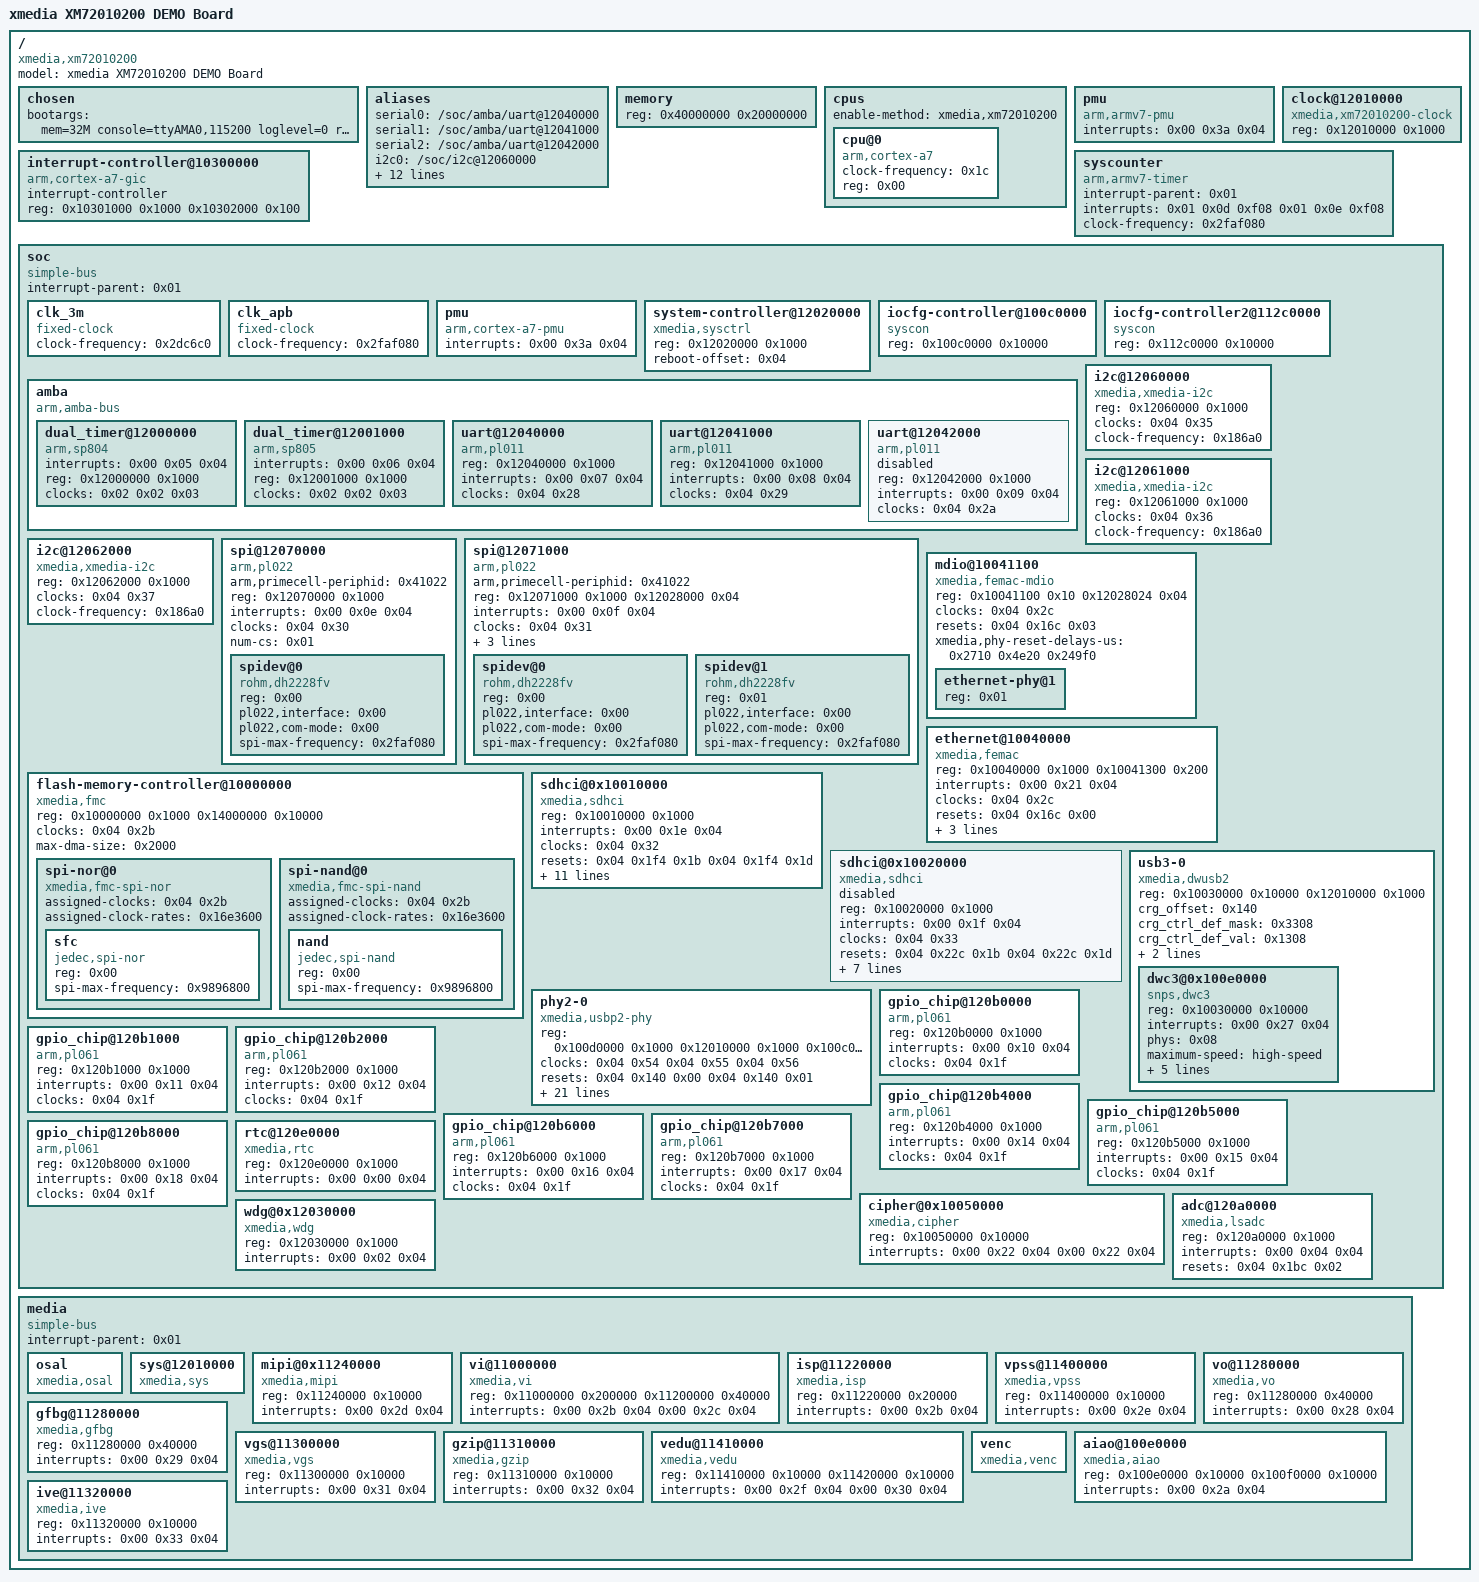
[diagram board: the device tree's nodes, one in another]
/dts-v1/;

/ {
	#address-cells = <0x01>;
	#size-cells = <0x01>;
	model = "xmedia XM72010200 DEMO Board";
	compatible = "xmedia,xm72010200";

	chosen {
		bootargs = "mem=32M console=ttyAMA0,115200 loglevel=0 root=/dev/mtdblock2 rootfstype=jffs2 rw mtdparts=sfc:128K(boot),3M(kernel),3M(rootfs)";
	};

	aliases {
		serial0 = "/soc/amba/uart@12040000";
		serial1 = "/soc/amba/uart@12041000";
		serial2 = "/soc/amba/uart@12042000";
		i2c0 = "/soc/i2c@12060000";
		i2c1 = "/soc/i2c@12061000";
		i2c2 = "/soc/i2c@12062000";
		spi0 = "/soc/spi@12070000";
		spi1 = "/soc/spi@12071000";
		gpio0 = "/soc/gpio_chip@120b0000";
		gpio1 = "/soc/gpio_chip@120b1000";
		gpio2 = "/soc/gpio_chip@120b2000";
		gpio4 = "/soc/gpio_chip@120b4000";
		gpio5 = "/soc/gpio_chip@120b5000";
		gpio6 = "/soc/gpio_chip@120b6000";
		gpio7 = "/soc/gpio_chip@120b7000";
		gpio8 = "/soc/gpio_chip@120b8000";
	};

	memory {
		device_type = "memory";
		reg = <0x40000000 0x20000000>;
	};

	cpus {
		#address-cells = <0x01>;
		#size-cells = <0x00>;
		enable-method = "xmedia,xm72010200";

		cpu@0 {
			device_type = "cpu";
			compatible = "arm,cortex-a7";
			clock-frequency = <0x1c>;
			reg = <0x00>;
		};
	};

	pmu {
		compatible = "arm,armv7-pmu";
		interrupts = <0x00 0x3a 0x04>;
	};

	clock@12010000 {
		compatible = "xmedia,xm72010200-clock\0syscon";
		#address-cells = <0x01>;
		#size-cells = <0x01>;
		#clock-cells = <0x01>;
		#reset-cells = <0x02>;
		reg = <0x12010000 0x1000>;
		linux,phandle = <0x04>;
		phandle = <0x04>;
	};

	interrupt-controller@10300000 {
		compatible = "arm,cortex-a7-gic";
		#interrupt-cells = <0x03>;
		#address-cells = <0x00>;
		interrupt-controller;
		reg = <0x10301000 0x1000 0x10302000 0x100>;
		linux,phandle = <0x01>;
		phandle = <0x01>;
	};

	syscounter {
		compatible = "arm,armv7-timer";
		interrupt-parent = <0x01>;
		interrupts = <0x01 0x0d 0xf08 0x01 0x0e 0xf08>;
		clock-frequency = <0x2faf080>;
	};

	soc {
		#address-cells = <0x01>;
		#size-cells = <0x01>;
		compatible = "simple-bus";
		interrupt-parent = <0x01>;
		ranges;

		clk_3m {
			compatible = "fixed-clock";
			#clock-cells = <0x00>;
			clock-frequency = <0x2dc6c0>;
			linux,phandle = <0x02>;
			phandle = <0x02>;
		};

		clk_apb {
			compatible = "fixed-clock";
			#clock-cells = <0x00>;
			clock-frequency = <0x2faf080>;
			linux,phandle = <0x03>;
			phandle = <0x03>;
		};

		pmu {
			compatible = "arm,cortex-a7-pmu";
			interrupts = <0x00 0x3a 0x04>;
		};

		system-controller@12020000 {
			compatible = "xmedia,sysctrl";
			reg = <0x12020000 0x1000>;
			reboot-offset = <0x04>;
			#clock-cells = <0x01>;
		};

		iocfg-controller@100c0000 {
			compatible = "syscon";
			reg = <0x100c0000 0x10000>;
			linux,phandle = <0x06>;
			phandle = <0x06>;
		};

		iocfg-controller2@112c0000 {
			compatible = "syscon";
			reg = <0x112c0000 0x10000>;
			linux,phandle = <0x07>;
			phandle = <0x07>;
		};

		amba {
			#address-cells = <0x01>;
			#size-cells = <0x01>;
			compatible = "arm,amba-bus";
			ranges;

			dual_timer@12000000 {
				compatible = "arm,sp804\0arm,primecell";
				interrupts = <0x00 0x05 0x04>;
				reg = <0x12000000 0x1000>;
				clocks = <0x02 0x02 0x03>;
				clock-names = "timer00\0timer01\0apb_pclk";
				status = "okay";
			};

			dual_timer@12001000 {
				compatible = "arm,sp805\0arm,primecel5";
				interrupts = <0x00 0x06 0x04>;
				reg = <0x12001000 0x1000>;
				clocks = <0x02 0x02 0x03>;
				clock-names = "timer10\0timer11\0apb_pclk";
				status = "okay";
			};

			uart@12040000 {
				compatible = "arm,pl011\0arm,primecell";
				reg = <0x12040000 0x1000>;
				interrupts = <0x00 0x07 0x04>;
				clocks = <0x04 0x28>;
				clock-names = "apb_pclk";
				status = "okay";
			};

			uart@12041000 {
				compatible = "arm,pl011\0arm,primecell";
				reg = <0x12041000 0x1000>;
				interrupts = <0x00 0x08 0x04>;
				clocks = <0x04 0x29>;
				clock-names = "apb_pclk";
				status = "okay";
			};

			uart@12042000 {
				compatible = "arm,pl011\0arm,primecell";
				reg = <0x12042000 0x1000>;
				interrupts = <0x00 0x09 0x04>;
				clocks = <0x04 0x2a>;
				clock-names = "apb_pclk";
				status = "disabled";
			};
		};

		i2c@12060000 {
			compatible = "xmedia,xmedia-i2c";
			reg = <0x12060000 0x1000>;
			clocks = <0x04 0x35>;
			status = "okay";
			clock-frequency = <0x186a0>;
		};

		i2c@12061000 {
			compatible = "xmedia,xmedia-i2c";
			reg = <0x12061000 0x1000>;
			clocks = <0x04 0x36>;
			status = "okay";
			clock-frequency = <0x186a0>;
		};

		i2c@12062000 {
			compatible = "xmedia,xmedia-i2c";
			reg = <0x12062000 0x1000>;
			clocks = <0x04 0x37>;
			status = "okay";
			clock-frequency = <0x186a0>;
		};

		spi@12070000 {
			compatible = "arm,pl022\0arm,primecell";
			arm,primecell-periphid = <0x41022>;
			reg = <0x12070000 0x1000>;
			interrupts = <0x00 0x0e 0x04>;
			clocks = <0x04 0x30>;
			clock-names = "apb_pclk";
			#address-cells = <0x01>;
			#size-cells = <0x00>;
			status = "okay";
			num-cs = <0x01>;

			spidev@0 {
				compatible = "rohm,dh2228fv";
				reg = <0x00>;
				pl022,interface = <0x00>;
				pl022,com-mode = <0x00>;
				spi-max-frequency = <0x2faf080>;
			};
		};

		spi@12071000 {
			compatible = "arm,pl022\0arm,primecell";
			arm,primecell-periphid = <0x41022>;
			reg = <0x12071000 0x1000 0x12028000 0x04>;
			interrupts = <0x00 0x0f 0x04>;
			clocks = <0x04 0x31>;
			clock-names = "apb_pclk";
			#address-cells = <0x01>;
			#size-cells = <0x00>;
			num-cs = <0x02>;
			spi_cs_sb = <0x02>;
			spi_cs_mask_bit = <0x04>;
			status = "okay";

			spidev@0 {
				compatible = "rohm,dh2228fv";
				reg = <0x00>;
				pl022,interface = <0x00>;
				pl022,com-mode = <0x00>;
				spi-max-frequency = <0x2faf080>;
			};

			spidev@1 {
				compatible = "rohm,dh2228fv";
				reg = <0x01>;
				pl022,interface = <0x00>;
				pl022,com-mode = <0x00>;
				spi-max-frequency = <0x2faf080>;
			};
		};

		mdio@10041100 {
			compatible = "xmedia,femac-mdio";
			reg = <0x10041100 0x10 0x12028024 0x04>;
			clocks = <0x04 0x2c>;
			clock-names = "mdio";
			resets = <0x04 0x16c 0x03>;
			reset-names = "internal-phy";
			#address-cells = <0x01>;
			#size-cells = <0x00>;
			xmedia,phy-reset-delays-us = <0x2710 0x4e20 0x249f0>;

			ethernet-phy@1 {
				reg = <0x01>;
				linux,phandle = <0x05>;
				phandle = <0x05>;
			};
		};

		ethernet@10040000 {
			compatible = "xmedia,femac\0xmedia,femac-v2";
			reg = <0x10040000 0x1000 0x10041300 0x200>;
			interrupts = <0x00 0x21 0x04>;
			clocks = <0x04 0x2c>;
			resets = <0x04 0x16c 0x00>;
			reset-names = "mac";
			mac-address = [00 00 00 00 00 00];
			phy-mode = "mii";
			phy-handle = <0x05>;
			status = "okay";
		};

		flash-memory-controller@10000000 {
			compatible = "xmedia,fmc";
			reg = <0x10000000 0x1000 0x14000000 0x10000>;
			reg-names = "control\0memory";
			clocks = <0x04 0x2b>;
			max-dma-size = <0x2000>;
			#address-cells = <0x01>;
			#size-cells = <0x00>;

			spi-nor@0 {
				compatible = "xmedia,fmc-spi-nor";
				assigned-clocks = <0x04 0x2b>;
				assigned-clock-rates = <0x16e3600>;
				#address-cells = <0x01>;
				#size-cells = <0x00>;

				sfc {
					compatible = "jedec,spi-nor";
					reg = <0x00>;
					spi-max-frequency = <0x9896800>;
				};
			};

			spi-nand@0 {
				compatible = "xmedia,fmc-spi-nand";
				assigned-clocks = <0x04 0x2b>;
				assigned-clock-rates = <0x16e3600>;
				#address-cells = <0x01>;
				#size-cells = <0x00>;

				nand {
					compatible = "jedec,spi-nand";
					reg = <0x00>;
					spi-max-frequency = <0x9896800>;
				};
			};
		};

		sdhci@0x10010000 {
			compatible = "xmedia,sdhci";
			reg = <0x10010000 0x1000>;
			interrupts = <0x00 0x1e 0x04>;
			clocks = <0x04 0x32>;
			clock-names = "mmc_clk";
			resets = <0x04 0x1f4 0x1b 0x04 0x1f4 0x1d>;
			reset-names = "crg_reset\0dll_reset";
			max-frequency = <0x17d7840>;
			crg_regmap = <0x04>;
			iocfg_regmap = <0x06>;
			bus-width = <0x04>;
			cap-mmc-highspeed;
			cap-mmc-hw-reset;
			cap-sd-highspeed;
			mmc-hs200-1_8v;
			sdhci,auto-cmd12;
			full-pwr-cycle;
			devid = <0x00>;
			status = "okay";
		};

		sdhci@0x10020000 {
			compatible = "xmedia,sdhci";
			reg = <0x10020000 0x1000>;
			interrupts = <0x00 0x1f 0x04>;
			clocks = <0x04 0x33>;
			clock-names = "mmc_clk";
			resets = <0x04 0x22c 0x1b 0x04 0x22c 0x1d>;
			reset-names = "crg_reset\0dll_reset";
			max-frequency = <0x2faf080>;
			crg_regmap = <0x04>;
			iocfg_regmap = <0x07>;
			bus-width = <0x04>;
			cap-sd-highspeed;
			full-pwr-cycle;
			devid = <0x02>;
			status = "disabled";
		};

		phy2-0 {
			compatible = "xmedia,usbp2-phy";
			reg = <0x100d0000 0x1000 0x12010000 0x1000 0x100c0000 0x1000>;
			clocks = <0x04 0x54 0x04 0x55 0x04 0x56>;
			clock-names = "clk_u2phy_apb_ref\0clk_u2phy_pll_ref\0clk_u2phy_xo_ref";
			resets = <0x04 0x140 0x00 0x04 0x140 0x01>;
			reset-names = "phy_por_reset\0phy_tpor_reset";
			phy_pll_offset = <0x14>;
			phy_pll_mask = <0x03>;
			phy_pll_val = <0x00>;
			crg_offset = <0x140>;
			crg_defal_mask = <0xc07>;
			crg_defal_val = <0x807>;
			vbus_offset = <0x7c>;
			vbus_val = <0x531>;
			pwren_offset = <0x80>;
			pwren_val = <0x01>;
			ana_cfg_0_eye_val = <0x433cc23>;
			ana_cfg_0_offset = <0x00>;
			ana_cfg_2_eye_val = <0x320f0f>;
			ana_cfg_2_offset = <0x08>;
			ana_cfg_4_eye_val = <0x655>;
			ana_cfg_4_offset = <0x10>;
			trim_otp_addr = <0x12028004>;
			trim_otp_mask = <0x1f>;
			trim_otp_bit_offset = <0x00>;
			trim_otp_min = <0x09>;
			trim_otp_max = <0x1d>;
			#phy-cells = <0x00>;
			linux,phandle = <0x08>;
			phandle = <0x08>;
		};

		usb3-0 {
			compatible = "xmedia,dwusb2";
			reg = <0x10030000 0x10000 0x12010000 0x1000>;
			#address-cells = <0x01>;
			#size-cells = <0x01>;
			crg_offset = <0x140>;
			crg_ctrl_def_mask = <0x3308>;
			crg_ctrl_def_val = <0x1308>;
			clocks = <0x04 0x51 0x04 0x52 0x04 0x53>;
			clock-names = "usb2_bus_clk\0usb2_ref_clk\0usb2_utmi_clk";
			resets = <0x04 0x140 0x03>;
			reset-names = "vcc_reset";
			ranges;

			dwc3@0x100e0000 {
				compatible = "snps,dwc3";
				reg = <0x10030000 0x10000>;
				interrupts = <0x00 0x27 0x04>;
				interrupt-names = "peripheral";
				phys = <0x08>;
				phy-names = "usb2-phy";
				maximum-speed = "high-speed";
				dr_mode = "host";
				eps_directions = <0x6a>;
				snps,eps_new_init;
				eps_map = <0x00 0x01 0x02 0x03 0x04 0x05 0x07>;
				snps,usb2-lpm-disable;
			};
		};

		gpio_chip@120b0000 {
			compatible = "arm,pl061\0arm,primecell";
			reg = <0x120b0000 0x1000>;
			interrupts = <0x00 0x10 0x04>;
			clocks = <0x04 0x1f>;
			clock-names = "apb_pclk";
			#gpio-cells = <0x02>;
			status = "okay";
		};

		gpio_chip@120b1000 {
			compatible = "arm,pl061\0arm,primecell";
			reg = <0x120b1000 0x1000>;
			interrupts = <0x00 0x11 0x04>;
			clocks = <0x04 0x1f>;
			clock-names = "apb_pclk";
			#gpio-cells = <0x02>;
			status = "okay";
		};

		gpio_chip@120b2000 {
			compatible = "arm,pl061\0arm,primecell";
			reg = <0x120b2000 0x1000>;
			interrupts = <0x00 0x12 0x04>;
			clocks = <0x04 0x1f>;
			clock-names = "apb_pclk";
			#gpio-cells = <0x02>;
			status = "okay";
		};

		gpio_chip@120b4000 {
			compatible = "arm,pl061\0arm,primecell";
			reg = <0x120b4000 0x1000>;
			interrupts = <0x00 0x14 0x04>;
			clocks = <0x04 0x1f>;
			clock-names = "apb_pclk";
			#gpio-cells = <0x02>;
			status = "okay";
		};

		gpio_chip@120b5000 {
			compatible = "arm,pl061\0arm,primecell";
			reg = <0x120b5000 0x1000>;
			interrupts = <0x00 0x15 0x04>;
			clocks = <0x04 0x1f>;
			clock-names = "apb_pclk";
			#gpio-cells = <0x02>;
			status = "okay";
		};

		gpio_chip@120b6000 {
			compatible = "arm,pl061\0arm,primecell";
			reg = <0x120b6000 0x1000>;
			interrupts = <0x00 0x16 0x04>;
			clocks = <0x04 0x1f>;
			clock-names = "apb_pclk";
			#gpio-cells = <0x02>;
			status = "okay";
		};

		gpio_chip@120b7000 {
			compatible = "arm,pl061\0arm,primecell";
			reg = <0x120b7000 0x1000>;
			interrupts = <0x00 0x17 0x04>;
			clocks = <0x04 0x1f>;
			clock-names = "apb_pclk";
			#gpio-cells = <0x02>;
			status = "okay";
		};

		gpio_chip@120b8000 {
			compatible = "arm,pl061\0arm,primecell";
			reg = <0x120b8000 0x1000>;
			interrupts = <0x00 0x18 0x04>;
			clocks = <0x04 0x1f>;
			clock-names = "apb_pclk";
			#gpio-cells = <0x02>;
			status = "okay";
		};

		rtc@120e0000 {
			compatible = "xmedia,rtc";
			reg = <0x120e0000 0x1000>;
			interrupts = <0x00 0x00 0x04>;
		};

		cipher@0x10050000 {
			compatible = "xmedia,cipher";
			reg = <0x10050000 0x10000>;
			reg-names = "cipher";
			interrupts = <0x00 0x22 0x04 0x00 0x22 0x04>;
			interrupt-names = "cipher\0hash";
		};

		adc@120a0000 {
			compatible = "xmedia,lsadc";
			reg = <0x120a0000 0x1000>;
			interrupts = <0x00 0x04 0x04>;
			interrupt-names = "adc";
			resets = <0x04 0x1bc 0x02>;
			reset-names = "lsadc-crg";
			status = "okay";
		};

		wdg@0x12030000 {
			compatible = "xmedia,wdg";
			reg = <0x12030000 0x1000>;
			reg-names = "wdg";
			interrupts = <0x00 0x02 0x04>;
			interrupt-names = "wdg";
		};
	};

	media {
		#address-cells = <0x01>;
		#size-cells = <0x01>;
		compatible = "simple-bus";
		interrupt-parent = <0x01>;
		ranges;

		osal {
			compatible = "xmedia,osal";
		};

		sys@12010000 {
			compatible = "xmedia,sys";
		};

		mipi@0x11240000 {
			compatible = "xmedia,mipi";
			reg = <0x11240000 0x10000>;
			reg-names = "mipi_rx";
			interrupts = <0x00 0x2d 0x04>;
			interrupt-names = "mipi_rx";
		};

		vi@11000000 {
			compatible = "xmedia,vi";
			reg = <0x11000000 0x200000 0x11200000 0x40000>;
			reg-names = "VI_CAP0\0VI_PROC0";
			interrupts = <0x00 0x2b 0x04 0x00 0x2c 0x04>;
			interrupt-names = "VI_CAP0\0VI_PROC0";
		};

		isp@11220000 {
			compatible = "xmedia,isp";
			reg = <0x11220000 0x20000>;
			reg-names = "ISP";
			interrupts = <0x00 0x2b 0x04>;
			interrupt-names = "ISP";
		};

		vpss@11400000 {
			compatible = "xmedia,vpss";
			reg = <0x11400000 0x10000>;
			reg-names = "vpss0";
			interrupts = <0x00 0x2e 0x04>;
			interrupt-names = "vpss0";
		};

		vo@11280000 {
			compatible = "xmedia,vo";
			reg = <0x11280000 0x40000>;
			reg-names = "vo";
			interrupts = <0x00 0x28 0x04>;
			interrupt-names = "vo";
		};

		gfbg@11280000 {
			compatible = "xmedia,gfbg";
			reg = <0x11280000 0x40000>;
			reg-names = "gfbg";
			interrupts = <0x00 0x29 0x04>;
			interrupt-names = "gfbg";
		};

		vgs@11300000 {
			compatible = "xmedia,vgs";
			reg = <0x11300000 0x10000>;
			reg-names = "vgs0";
			interrupts = <0x00 0x31 0x04>;
			interrupt-names = "vgs0";
		};

		gzip@11310000 {
			compatible = "xmedia,gzip";
			reg = <0x11310000 0x10000>;
			reg-names = "gzip";
			interrupts = <0x00 0x32 0x04>;
			interrupt-names = "gzip";
		};

		vedu@11410000 {
			compatible = "xmedia,vedu";
			reg = <0x11410000 0x10000 0x11420000 0x10000>;
			reg-names = "vedu0\0jpge";
			interrupts = <0x00 0x2f 0x04 0x00 0x30 0x04>;
			interrupt-names = "vedu0\0jpge";
		};

		venc {
			compatible = "xmedia,venc";
		};

		aiao@100e0000 {
			compatible = "xmedia,aiao";
			reg = <0x100e0000 0x10000 0x100f0000 0x10000>;
			reg-names = "aiao\0acodec";
			interrupts = <0x00 0x2a 0x04>;
			interrupt-names = "AIO";
		};

		ive@11320000 {
			compatible = "xmedia,ive";
			reg = <0x11320000 0x10000>;
			reg-names = "ive";
			interrupts = <0x00 0x33 0x04>;
			interrupt-names = "ive";
		};
	};
};
